# STM32H5F4 register map
File version: 1.0
CPU: CM33 r0p0, little endian, MPU, FPU, 4 interrupt priority bits
Registers are 32-bit, read-write, reset 0x0 unless marked. A register's access mark holds for its fields unless they carry their own. Offsets are from the block's base; [hi:lo] are bit positions; {n}, {i} and the like mark numbered series; 'fields as' and 'values as' point back to an identical list.

## OTFDEC1 — OTFDEC1 register bank
Base 0x46005000
Same registers: OTFDEC2 0x46005400, OTFDEC1_S 0x56005000, OTFDEC2_S 0x56005400
0x00 OTFDEC1_CR — OTFDEC control register
  [0] ENC — Encryption mode bit
    0=OTFDEC working in decryption mode; 1=OTFDEC working in encryption mode
0x10 OTFDEC1_PRIVCFGR — OTFDEC privileged access control configuration register
  [0] PRIV — Privileged access protection.
    0=No additional protection is added on OTFDEC register accesses; 1=An additional protection is added when accessing all registers except OTFDEC_PRIVCFGR:
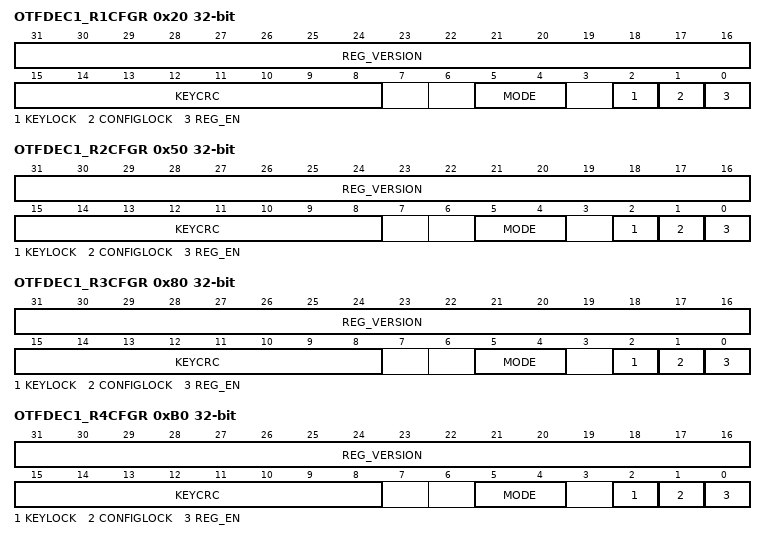
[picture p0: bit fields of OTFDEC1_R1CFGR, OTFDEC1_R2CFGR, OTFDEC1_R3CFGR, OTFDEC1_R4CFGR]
0x20 OTFDEC1_R1CFGR — OTFDEC region 1 configuration register
  [31:16] REG_VERSION — region firmware version
  [15:8] KEYCRC ro — region key 8-bit CRC
  [5:4] MODE — operating mode
    2=All read accesses are decrypted (instruction or data); 3=Enhanced encryption mode is activated, and only instruction accesses are decrypted
  [2] KEYLOCK — region key lock
    0=Writes to this region KEYRx registers are allowed; 1=Writes to this region KEYRx registers are ignored until next OTFDEC reset
  [1] CONFIGLOCK — region config lock
    0=Writes to this region OTFDEC_RxCFGR, OTFDEC_RxSTARTADDR, OTFDEC_RxENDADDR and OTFDEC_RxNONCERy registers are allowed; 1=Writes to this region OTFDEC_RxCFGR, OTFDEC_RxSTARTADDR, OTFDEC_RxENDADDR and OTFDEC_RxNONCERy registers are ignored until next OTFDEC reset
  [0] REG_EN — region on-the-fly decryption enable
    0=On-the-fly decryption is disabled for this region; 1=On-the-fly decryption is enabled for this region
0x24 OTFDEC1_R1STARTADDR — OTFDEC region 1 start address register
  [31:0] REG_START_ADDR — Region AHB start address
0x28 OTFDEC1_R1ENDADDR reset 0xFFF — OTFDEC region 1 end address register
  [31:0] REG_END_ADDR — Region AHB end address
0x2C OTFDEC1_R1NONCER0 — OTFDEC region 1 nonce register 0
  [31:0] REG_NONCE — Region nonce, bits [31:0]
{0x0+0x30*i} OTFDEC1_R{i}NONCER1 (i=1..4) — OTFDEC region {i} nonce register 1
  [31:0] REG_NONCE — Region nonce, bits [63:32]
{0x4+0x30*i} OTFDEC1_R{i}KEYR0 wo (i=1..4) — OTFDEC region {i} key register 0
  [31:0] REG_KEY — Region key, bits [31:0]
{0x8+0x30*i} OTFDEC1_R{i}KEYR1 wo (i=1..4) — OTFDEC region {i} key register 1
  [31:0] REG_KEY — Region key, bits [63:32]
{0xC+0x30*i} OTFDEC1_R{i}KEYR2 wo (i=1..4) — OTFDEC region {i} key register 2
  [31:0] REG_KEY — Region key, bits [95:64]
{0x10+0x30*i} OTFDEC1_R{i}KEYR3 wo (i=1..4) — OTFDEC region {i} key register 3
  [31:0] REG_KEY — Region key, bits [127:96]
0x50 OTFDEC1_R2CFGR — OTFDEC region 2 configuration register
  fields as OTFDEC1_R1CFGR
0x54 OTFDEC1_R2STARTADDR — OTFDEC region 2 start address register
  [31:0] REG_START_ADDR — Region AHB start address
0x58 OTFDEC1_R2ENDADDR reset 0xFFF — OTFDEC region 2 end address register
  [31:0] REG_END_ADDR — Region AHB end address
0x5C OTFDEC1_R2NONCER0 — OTFDEC region 2 nonce register 0
  [31:0] REG_NONCE — Region nonce, bits [31:0]
0x80 OTFDEC1_R3CFGR — OTFDEC region 3 configuration register
  fields as OTFDEC1_R1CFGR
0x84 OTFDEC1_R3STARTADDR — OTFDEC region 3 start address register
  [31:0] REG_START_ADDR — Region AHB start address
0x88 OTFDEC1_R3ENDADDR reset 0xFFF — OTFDEC region 3 end address register
  [31:0] REG_END_ADDR — Region AHB end address
0x8C OTFDEC1_R3NONCER0 — OTFDEC region 3 nonce register 0
  [31:0] REG_NONCE — Region nonce, bits [31:0]
0xB0 OTFDEC1_R4CFGR — OTFDEC region 4 configuration register
  fields as OTFDEC1_R1CFGR
0xB4 OTFDEC1_R4STARTADDR — OTFDEC region 4 start address register
  [31:0] REG_START_ADDR — Region AHB start address
0xB8 OTFDEC1_R4ENDADDR reset 0xFFF — OTFDEC region 4 end address register
  [31:0] REG_END_ADDR — Region AHB end address
0xBC OTFDEC1_R4NONCER0 — OTFDEC region 4 nonce register 0
  [31:0] REG_NONCE — Region nonce, bits [31:0]
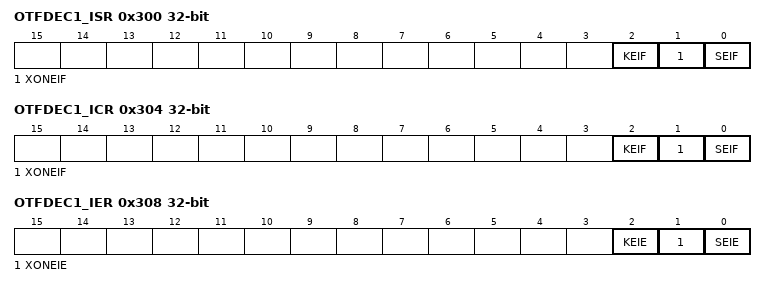
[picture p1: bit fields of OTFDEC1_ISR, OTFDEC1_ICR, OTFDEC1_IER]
0x300 OTFDEC1_ISR ro — OTFDEC interrupt status register
  [2] KEIF — Key error interrupt flag status
    0=OTFDEC operates properly; 1=Read access detected on an enabled encrypted region with its key registers null or not properly initialized (KEYCRC=0x0)
  [1] XONEIF — Execute-only execute-never error interrupt flag status
    0=No execute-only error status; 1=Read access detected on one region with MODE bits set to 11 or execute access detected while ENC=1
  [0] SEIF — Security error interrupt flag status
    0=No security error status; 1=Security error flag status, with interrupt pending
0x304 OTFDEC1_ICR wo — OTFDEC interrupt clear register
  [2] KEIF — Key error interrupt flag clear
    0=KEIF flag status is not affected; 1=KEIF flag status is cleared in OTFDEC_ISR
  [1] XONEIF — Execute-only execute-never error interrupt flag clear
    0=XONEIF flag status is not affected; 1=XONEIF flag status is cleared in OTFDEC_ISR
  [0] SEIF — Security error interrupt flag clear
    0=SEIF flag status is not affected; 1=SEIF flag status is cleared in OTFDEC_ISR
0x308 OTFDEC1_IER — OTFDEC interrupt enable register
  [2] KEIE — Key error interrupt enable
    0=Interrupt generation on key error flag KEIF is disabled (masked); 1=Interrupt generation on key error flag KEIF is enabled (not masked)
  [1] XONEIE — Execute-only execute-never error interrupt enable
    0=Interrupt generation on execute-only error XONEIF is disabled (masked); 1=Interrupt generation on execute-only error XONEIF is enabled (not masked)
  [0] SEIE — Security error interrupt enable
    0=Interrupt generation on security error SEIF is disabled (masked); 1=Interrupt generation on security error SEIF is enabled (not masked)
